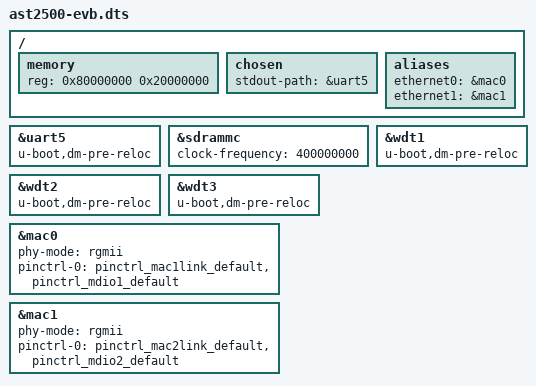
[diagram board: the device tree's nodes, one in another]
/dts-v1/;

#include "ast2500-u-boot.dtsi"

/ {
	memory {
		device_type = "memory";
		reg = <0x80000000 0x20000000>;
	};

	chosen {
		stdout-path = &uart5;
	};

	aliases {
		ethernet0 = &mac0;
		ethernet1 = &mac1;
	};
};

&uart5 {
	u-boot,dm-pre-reloc;
	status = "okay";
};

&sdrammc {
	clock-frequency = <400000000>;
};

&wdt1 {
	u-boot,dm-pre-reloc;
	status = "okay";
};

&wdt2 {
	u-boot,dm-pre-reloc;
	status = "okay";
};

&wdt3 {
	u-boot,dm-pre-reloc;
	status = "okay";
};

&mac0 {
	status = "okay";

	phy-mode = "rgmii";

	pinctrl-names = "default";
	pinctrl-0 = <&pinctrl_mac1link_default &pinctrl_mdio1_default>;
};

&mac1 {
	status = "okay";

	phy-mode = "rgmii";

	pinctrl-names = "default";
	pinctrl-0 = <&pinctrl_mac2link_default &pinctrl_mdio2_default>;
};
